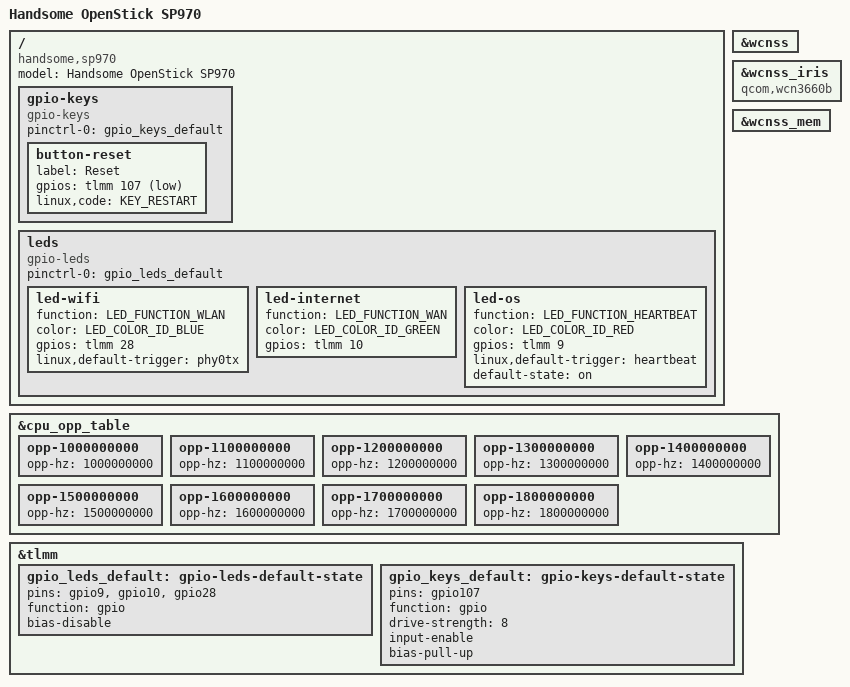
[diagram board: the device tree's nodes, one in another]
// SPDX-License-Identifier: GPL-2.0-only
/*
 * Handsome OpenStick SP970 - MSM8916 4G USB stick
 *
 * Board layout (based on HandsomeMod 5.10 DTS):
 *   - Wi-Fi/BT: WCN3660b (pronto v2)
 *   - Reset button: GPIO 107
 *   - LEDs: wifi=28, internet=10, os=9
 *   - No SIM-select LEDs
 *   - eMMC: sdhc_1
 */

/dts-v1/;

#include "msm8916-handsome-openstick-common.dtsi"
#include <dt-bindings/leds/common.h>

/ {
	model = "Handsome OpenStick SP970";
	compatible = "handsome,sp970", "qcom,msm8916";

	gpio-keys {
		compatible = "gpio-keys";

		pinctrl-names = "default";
		pinctrl-0 = <&gpio_keys_default>;

		button-reset {
			label = "Reset";
			gpios = <&tlmm 107 GPIO_ACTIVE_LOW>;
			linux,code = <KEY_RESTART>;
		};
	};

	leds {
		compatible = "gpio-leds";

		pinctrl-names = "default";
		pinctrl-0 = <&gpio_leds_default>;

		led-wifi {
			function = LED_FUNCTION_WLAN;
			color = <LED_COLOR_ID_BLUE>;
			gpios = <&tlmm 28 GPIO_ACTIVE_HIGH>;
			linux,default-trigger = "phy0tx";
		};

		led-internet {
			function = LED_FUNCTION_WAN;
			color = <LED_COLOR_ID_GREEN>;
			gpios = <&tlmm 10 GPIO_ACTIVE_HIGH>;
		};

		led-os {
			function = LED_FUNCTION_HEARTBEAT;
			color = <LED_COLOR_ID_RED>;
			gpios = <&tlmm 9 GPIO_ACTIVE_HIGH>;
			linux,default-trigger = "heartbeat";
			default-state = "on";
		};
	};
};

&wcnss {
	status = "okay";
};

&wcnss_iris {
	compatible = "qcom,wcn3660b";
};

&wcnss_mem {
	status = "okay";
};

/*
 * CPU overclocking (SAW2 auto-scales via pm8916_s3).
 * SP970 is known fast, but we cap at 1.8GHz for stability
 * (bin can reach 2.1GHz but not guaranteed across units).
 */
&cpu_opp_table {
	opp-1000000000 {
		opp-hz = /bits/ 64 <1000000000>;
	};
	opp-1100000000 {
		opp-hz = /bits/ 64 <1100000000>;
	};
	opp-1200000000 {
		opp-hz = /bits/ 64 <1200000000>;
	};
	opp-1300000000 {
		opp-hz = /bits/ 64 <1300000000>;
	};
	opp-1400000000 {
		opp-hz = /bits/ 64 <1400000000>;
	};
	opp-1500000000 {
		opp-hz = /bits/ 64 <1500000000>;
	};
	opp-1600000000 {
		opp-hz = /bits/ 64 <1600000000>;
	};
	opp-1700000000 {
		opp-hz = /bits/ 64 <1700000000>;
	};
	opp-1800000000 {
		opp-hz = /bits/ 64 <1800000000>;
	};
};

&tlmm {
	gpio_leds_default: gpio-leds-default-state {
		pins = "gpio9", "gpio10", "gpio28";
		function = "gpio";
		bias-disable;
	};

	gpio_keys_default: gpio-keys-default-state {
		pins = "gpio107";
		function = "gpio";

		drive-strength = <8>;
		input-enable;
		bias-pull-up;
	};
};
